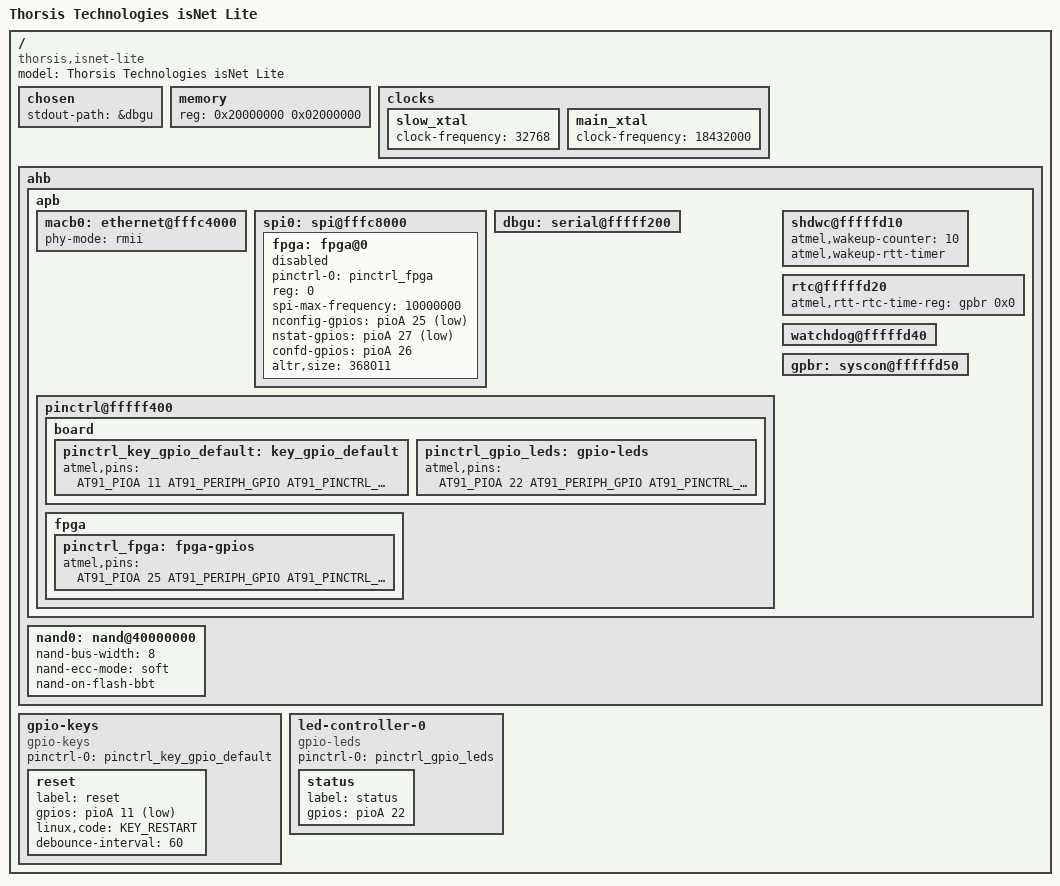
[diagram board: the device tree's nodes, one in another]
// SPDX-License-Identifier: GPL-2.0
/*
 * at91-isnet_lite.dts -- Device Tree file for Thorsis Technologies isNet Lite board
 *
 * Copyright 2022 Thorsis Technologies GmbH
 *
 * Author: Alexander Dahl <ada@thorsis.com>
 */
/dts-v1/;
#include "at91sam9g20.dtsi"
#include <dt-bindings/input/input.h>

/ {
	model = "Thorsis Technologies isNet Lite";
	compatible = "thorsis,isnet-lite", "atmel,at91sam9g20", "atmel,at91sam9";

	chosen {
		stdout-path = &dbgu;
	};

	memory {
		reg = <0x20000000 0x02000000>;
	};

	clocks {
		slow_xtal {
			clock-frequency = <32768>;
		};

		main_xtal {
			clock-frequency = <18432000>;
		};
	};

	ahb {
		apb {
			macb0: ethernet@fffc4000 {
				phy-mode = "rmii";
				status = "okay";
			};

			spi0: spi@fffc8000 {
				fpga: fpga@0 {
					pinctrl-names = "default";
					pinctrl-0 = <&pinctrl_fpga>;
					status = "disabled";
					reg = <0>;
					spi-max-frequency = <10000000>;
					nconfig-gpios = <&pioA 25 GPIO_ACTIVE_LOW>;
					nstat-gpios = <&pioA 27 GPIO_ACTIVE_LOW>;
					confd-gpios = <&pioA 26 GPIO_ACTIVE_HIGH>;
					altr,size = <368011>;	// EP3C5
				};
			};

			dbgu: serial@fffff200 {
				status = "okay";
			};

			pinctrl@fffff400 {
				board {
					pinctrl_key_gpio_default: key_gpio_default {
						atmel,pins = <AT91_PIOA 11 AT91_PERIPH_GPIO AT91_PINCTRL_DEGLITCH>;
					};

					pinctrl_gpio_leds: gpio-leds {
						atmel,pins = <AT91_PIOA 22 AT91_PERIPH_GPIO AT91_PINCTRL_NONE>;
					};
				};

				fpga {
					pinctrl_fpga: fpga-gpios {
						atmel,pins =
							<AT91_PIOA 25 AT91_PERIPH_GPIO AT91_PINCTRL_NONE	/* nCONFIG     */
							 AT91_PIOA 26 AT91_PERIPH_GPIO AT91_PINCTRL_NONE	/* CONF_DONE   */
							 AT91_PIOA 27 AT91_PERIPH_GPIO AT91_PINCTRL_NONE>;	/* nSTATUS     */
					};
				};
			};

			shdwc@fffffd10 {
				atmel,wakeup-counter = <10>;
				atmel,wakeup-rtt-timer;
			};

			rtc@fffffd20 {
				atmel,rtt-rtc-time-reg = <&gpbr 0x0>;
				status = "okay";
			};

			watchdog@fffffd40 {
				status = "okay";
			};

			gpbr: syscon@fffffd50 {
				status = "okay";
			};
		};

		nand0: nand@40000000 {
			nand-bus-width = <8>;
			nand-ecc-mode = "soft";
			nand-on-flash-bbt;
			status = "okay";

			/* maybe add partitions here later */
		};
	};

	gpio-keys {
		compatible = "gpio-keys";
		status = "okay";

		pinctrl-names = "default";
		pinctrl-0 = <&pinctrl_key_gpio_default>;

		/* label is used as is to identify button in U-Boot shell command */
		reset {
			label = "reset";
			gpios = <&pioA 11 GPIO_ACTIVE_LOW>;
			linux,code = <KEY_RESTART>;
			debounce-interval = <60>;
		};
	};

	led-controller-0 {
		compatible = "gpio-leds";
		status = "okay";

		pinctrl-names = "default";
		pinctrl-0 = <&pinctrl_gpio_leds>;

		/* name/label same as in dtb for Linux */
		status {
			label = "status";
			gpios = <&pioA 22 GPIO_ACTIVE_HIGH>;
		};
	};
};
